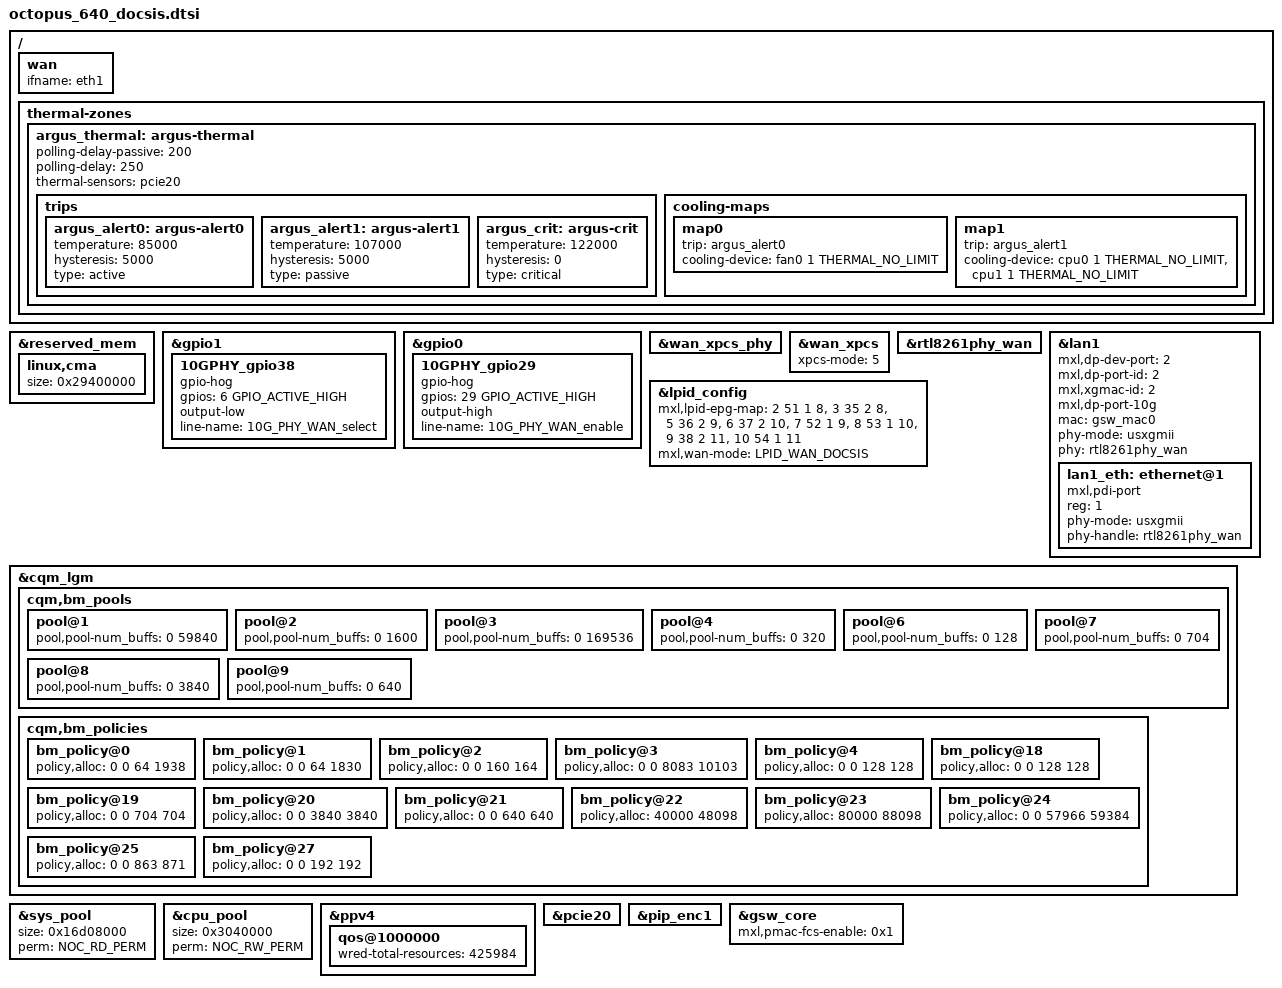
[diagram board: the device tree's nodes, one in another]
// SPDX-License-Identifier: GPL-2.0
/*
 * Copyright (C) 2024 MaxLinear, Inc.
 */

&reserved_mem {
linux,cma {
	size = <0x29400000>;
	};
};

/* 10G WAN PHY as LAN */

/* Select 10G PHY WAN */
&gpio1 {
	10GPHY_gpio38 {
		gpio-hog;
		gpios = <6 GPIO_ACTIVE_HIGH>;
		output-low;
		line-name = "10G_PHY_WAN_select";
	};
};

/* Enable 10G PHY WAN */
&gpio0 {
	10GPHY_gpio29 {
		gpio-hog;
		gpios = <29 GPIO_ACTIVE_HIGH>;
		output-high;
		line-name = "10G_PHY_WAN_enable";
	};
};

/ {
	wan {
		ifname = "eth1";
	};
};

/* WAN XPCS PHY */
&wan_xpcs_phy {
	status = "okay";
};

&wan_xpcs {
	status = "okay";
	xpcs-mode = <5>; /* USXGMII */
};

&rtl8261phy_wan {
	status = "okay";
};

&lan1 {
	status = "okay";

	mxl,dp-dev-port = <2>;
	mxl,dp-port-id = <2>;
	mxl,xgmac-id = <2>;
	mxl,dp-port-10g;
	mac = <&gsw_mac0>;
	phy-mode = "usxgmii";
	phy = <&rtl8261phy_wan>;

	lan1_eth: ethernet@1 {
		compatible = "mxl,pdi-port";
		reg = <1>;
		phy-mode = "usxgmii";
		phy-handle = <&rtl8261phy_wan>;
	};
};

/* todo: should be moved to /sdk/feed_target_x86/intel_x86/dts/lgp_thermal.dtsi */
/ {
	thermal-zones {
		argus_thermal: argus-thermal {
			polling-delay-passive = <200>; /* milliseconds */
			polling-delay = <250>; /* milliseconds */

			thermal-sensors = <>; /* should define in *_docsis.dts */

			trips {
				argus_alert0: argus-alert0 {
					temperature = <85000>; /* millicelsius */
					hysteresis = <5000>; /* millicelsius */
					type = "active";
				};
				argus_alert1: argus-alert1 {
					temperature = <107000>; /* millicelsius */
					hysteresis = <5000>; /* millicelsius */
					type = "passive";
				};
				argus_crit: argus-crit {
					temperature = <122000>;
					hysteresis = <0>;
					type = "critical";
				};
			};

			cooling-maps {
				map0 {
					trip = <&argus_alert0>;
					cooling-device = <&fan0 1 THERMAL_NO_LIMIT>;
				};
				map1 {
					trip = <&argus_alert1>;
					cooling-device = <&cpu0 1 THERMAL_NO_LIMIT>,
							 <&cpu1 1 THERMAL_NO_LIMIT>;
				};
			};
		};
	};
};

&lpid_config {
	mxl,lpid-epg-map = <2 51 1 8>,
				<3 35 2 8>,
				<5 36 2 9>,
				<6 37 2 10>,
				<7 52 1 9>,
				<8 53 1 10>,
				<9 38 2 11>,
				<10 54 1 11>;
	mxl,wan-mode = <LPID_WAN_DOCSIS>;
};

&cqm_lgm {
	cqm,bm_pools {
		pool@1 {
			pool,pool-num_buffs = <0 59840>;
		};
		pool@2 {
			pool,pool-num_buffs = <0 1600>;
		};
		pool@3 {
			pool,pool-num_buffs = <0 169536>;
		};
		pool@4 {
			pool,pool-num_buffs = <0 320>;
		};
		pool@6 {
			pool,pool-num_buffs = <0 128>;
		};
		pool@7 {
			pool,pool-num_buffs = <0 704>;
		};
		pool@8 {
			pool,pool-num_buffs = <0 3840>;
		};
		pool@9 {
			pool,pool-num_buffs = <0 640>;
		};
	};
	cqm,bm_policies {
		/delete-node/ bm_policy@6;
		/delete-node/ bm_policy@7;
		/delete-node/ bm_policy@8;
		/delete-node/ bm_policy@9;
		/delete-node/ bm_policy@10;
		/delete-node/ bm_policy@11;
		/delete-node/ bm_policy@12;
		/delete-node/ bm_policy@13;
		/delete-node/ bm_policy@14;
		/delete-node/ bm_policy@15;
		/delete-node/ bm_policy@16;

		bm_policy@0 {
			policy,alloc = <0 0 64 1938>;
		};
		bm_policy@1 {
			policy,alloc = <0 0 64 1830>;
		};
		bm_policy@2 {
			policy,alloc = <0 0  160 164>;
		};
		bm_policy@3 {
			policy,alloc = <0 0 8083 10103>;
		};
		bm_policy@4 {
			policy,alloc = <0 0 128 128>;
		};
		bm_policy@18 {
			policy,alloc = <0 0 128 128>;
		};
		bm_policy@19 {
			policy,alloc = <0 0 704 704>;
		};
		bm_policy@20 {
			policy,alloc = <0 0 3840 3840>;
		};
		bm_policy@21 {
			policy,alloc = <0 0 640 640>;
		};
		bm_policy@22 {
			policy,alloc = <40000 48098>;
		};
		bm_policy@23 {
			policy,alloc = <80000 88098>;
		};
		bm_policy@24 {
			policy,alloc = <0 0 57966 59384>;
		};
		bm_policy@25 {
			policy,alloc = <0 0 863 871>;
		};
		bm_policy@27 {
			policy,alloc = <0 0 192 192>;
		};
	};
};

&sys_pool {
	size = <0x16d08000>;
	perm = <NOC_RD_PERM>;
};

&cpu_pool {
	size = <0x3040000>;
	perm = <NOC_RW_PERM>;
};

&ppv4 {
	qos@1000000 {
		wred-total-resources = <425984>;
	};
};

&pcie20 {
	#thermal-sensor-cells = <0>;
};

&argus_thermal {
	thermal-sensors = <&pcie20>;
};

&pip_enc1 {
	status = "okay";
};

&gsw_core {
	mxl,pmac-fcs-enable = <0x1>; /* set bit 0, i.e. set FCSEN for PMAC0 */
};
